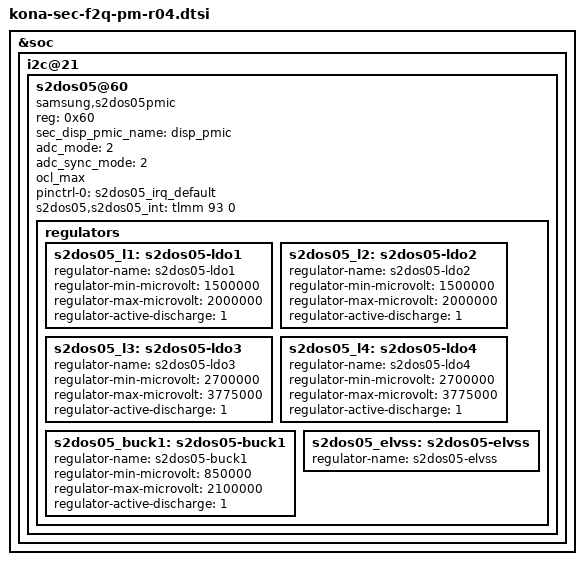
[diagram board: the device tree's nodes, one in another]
/* Copyright (c) 20, The Linux Foundation. All rights reserved.
 *
 * This program is free software; you can redistribute it and/or modify
 * it under the terms of the GNU General Public License version 2 and
 * only version 2 as published by the Free Software Foundation.
 *
 * This program is distributed in the hope that it will be useful,
 * but WITHOUT ANY WARRANTY; without even the implied warranty of
 * MERCHANTABILITY or FITNESS FOR A PARTICULAR PURPOSE.  See the
 * GNU General Public License for more details.
 */

/delete-node/ &s2dos06_60;
/delete-node/ &s2dos05_61;

&soc {
	i2c@21 {
		/* Main Display PMIC(SM3080 GND), Slave Address:C0 */
		s2dos05@60 {
			compatible = "samsung,s2dos05pmic";
			reg = <0x60>;
			sec_disp_pmic_name = "disp_pmic";
			adc_mode = <2>; /* 0 : disable, 1 : current meter, 2 : power meter */
			adc_sync_mode = <2>; /* 1 : sync mode, 2 : async mode */
			ocl_max; /* If this property exists, OCL_ELVDD and OCL_ELVSS will be set to 1.9A */

			pinctrl-names = "default";
			pinctrl-0 = <&s2dos05_irq_default>;
			s2dos05,s2dos05_int = <&tlmm 93 0>;

			regulators {
				s2dos05_l1: s2dos05-ldo1 {
					regulator-name = "s2dos05-ldo1";
					regulator-min-microvolt = <1500000>;
					regulator-max-microvolt = <2000000>;
					regulator-active-discharge = <1>;
				};

				s2dos05_l2: s2dos05-ldo2 {
					regulator-name = "s2dos05-ldo2";
					regulator-min-microvolt = <1500000>;
					regulator-max-microvolt = <2000000>;
					regulator-active-discharge = <1>;
				};

				s2dos05_l3: s2dos05-ldo3 {
					regulator-name = "s2dos05-ldo3";
					regulator-min-microvolt = <2700000>;
					regulator-max-microvolt = <3775000>;
					regulator-active-discharge = <1>;
				};

				s2dos05_l4: s2dos05-ldo4 {
					regulator-name = "s2dos05-ldo4";
					regulator-min-microvolt = <2700000>;
					regulator-max-microvolt = <3775000>;
					regulator-active-discharge = <1>;
				};

				s2dos05_buck1: s2dos05-buck1 {
					regulator-name = "s2dos05-buck1";
					regulator-min-microvolt = <850000>;
					regulator-max-microvolt = <2100000>;
					regulator-active-discharge = <1>;
				};

				s2dos05_elvss: s2dos05-elvss {
					regulator-name = "s2dos05-elvss";
				};
			};
		};
	};
};
